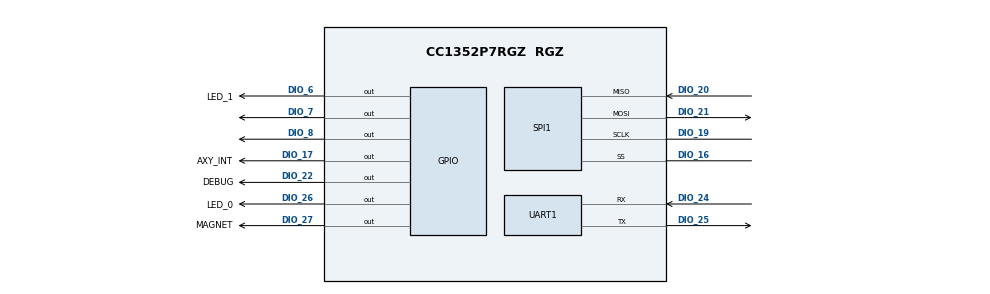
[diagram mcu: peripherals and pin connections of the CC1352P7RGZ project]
/**
 * @cliArgs --device "CC1352P7RGZ" --package "RGZ" --part "Default" --rtos "tirtos" --product "simplelink_cc13xx_cc26xx_sdk@6.10.00.29"
 * @versions {"tool":"1.12.0+2406"}
 */

/**
 * Import the modules used in this configuration.
 */
const ble         = scripting.addModule("/ti/ble5stack/ble");
const CCFG        = scripting.addModule("/ti/devices/CCFG");
const rfdesign    = scripting.addModule("/ti/devices/radioconfig/rfdesign");
const AESCCM      = scripting.addModule("/ti/drivers/AESCCM");
const AESCCM1     = AESCCM.addInstance();
const AESCTRDRBG  = scripting.addModule("/ti/drivers/AESCTRDRBG");
const AESCTRDRBG1 = AESCTRDRBG.addInstance();
const AESECB      = scripting.addModule("/ti/drivers/AESECB");
const AESECB1     = AESECB.addInstance();
const ECDH        = scripting.addModule("/ti/drivers/ECDH");
const ECDH1       = ECDH.addInstance();
const GPIO        = scripting.addModule("/ti/drivers/GPIO");
const GPIO1       = GPIO.addInstance();
const GPIO2       = GPIO.addInstance();
const GPIO3       = GPIO.addInstance();
const GPIO4       = GPIO.addInstance();
const GPIO5       = GPIO.addInstance();
const GPIO6       = GPIO.addInstance();
const GPIO7       = GPIO.addInstance();
const NVS         = scripting.addModule("/ti/drivers/NVS");
const NVS1        = NVS.addInstance();
const NVS2        = NVS.addInstance();
const NVS3        = NVS.addInstance();
const Power       = scripting.addModule("/ti/drivers/Power");
const RF          = scripting.addModule("/ti/drivers/RF");
const SPI         = scripting.addModule("/ti/drivers/SPI", {}, false);
const SPI1        = SPI.addInstance();
const TRNG        = scripting.addModule("/ti/drivers/TRNG");
const TRNG1       = TRNG.addInstance();
const UART        = scripting.addModule("/ti/drivers/UART", {}, false);
const UART1       = UART.addInstance();

/**
 * Write custom configuration values to the imported modules.
 */
ble.deviceRole                                            = "PERIPHERAL_CFG+CENTRAL_CFG";
ble.disDevBySerUuid                                       = true;
ble.numOfAdvSets                                          = 1;
ble.numOfDefAdvSets                                       = 1;
ble.maxConnNum                                            = 1;
ble.disableDisplayModule                                  = true;
ble.advRptFields                                          = ["SCAN_ADVRPT_FLD_ADDRESS","SCAN_ADVRPT_FLD_ADDRTYPE","SCAN_ADVRPT_FLD_RSSI"];
ble.randomAddress                                         = "A2:00:00:00:00:00";
ble.addressMode                                           = "ADDRMODE_PUBLIC";
ble.deviceName                                            = "Juxta";
ble.bondMITMProtection                                    = false;
ble.radioConfig.txPower                                   = "0";
ble.radioConfig.codeExportConfig.$name                    = "ti_devices_radioconfig_code_export_param0";
ble.connUpdateParamsPeripheral.$name                      = "ti_ble5stack_general_ble_conn_update_params0";
ble.connUpdateParamsPeripheral.reqMinConnInt              = 100;
ble.connUpdateParamsPeripheral.reqMaxConnInt              = 200;
ble.advSet1.$name                                         = "ti_ble5stack_broadcaster_advertisement_set0";
ble.advSet1.advParam1.$name                               = "ti_ble5stack_broadcaster_advertisement_params0";
ble.advSet1.advData1.$name                                = "ti_ble5stack_broadcaster_advertisement_data0";
ble.advSet1.advData1.GAP_ADTYPE_FLAGS                     = true;
ble.advSet1.advData1.advertisingFlags                     = ["GAP_ADTYPE_FLAGS_BREDR_NOT_SUPPORTED","GAP_ADTYPE_FLAGS_GENERAL"];
ble.advSet1.advData1.GAP_ADTYPE_16BIT_MORE                = true;
ble.advSet1.advData1.numOfUUIDs16More                     = 1;
ble.advSet1.advData1.UUID016More                          = 0xA2A2;
ble.advSet1.scanRes1.$name                                = "ti_ble5stack_broadcaster_advertisement_data1";
ble.advSet1.scanRes1.GAP_ADTYPE_SLAVE_CONN_INTERVAL_RANGE = true;
ble.advSet1.scanRes1.maxConnInterval                      = 130;
ble.advSet1.scanRes1.GAP_ADTYPE_POWER_LEVEL               = true;
ble.connUpdateParamsCentral.$name                         = "ti_ble5stack_general_ble_conn_update_params1";

CCFG.xoscCapArrayDelta        = 0xC1;
CCFG.enableBootloaderBackdoor = true;
CCFG.dioBootloaderBackdoor    = 15;
CCFG.levelBootloaderBackdoor  = "Active low";
CCFG.srcClkLF                 = "LF RCOSC";
CCFG.ccfgTemplate.$name       = "ti_devices_CCFG_CCFGCC26XXTemplate0";

rfdesign.fbSub1g = "none";
rfdesign.pa20    = "none";

AESCCM1.$name = "CONFIG_AESCCM0";

AESCTRDRBG1.$name              = "CONFIG_AESCTRDRBG_0";
AESCTRDRBG1.aesctrObject.$name = "CONFIG_AESCTR_0";

AESECB1.$name = "CONFIG_AESECB0";

ECDH1.$name = "CONFIG_ECDH0";

GPIO1.$name           = "LED_1";
GPIO1.mode            = "Output";
GPIO1.outputStrength  = "Low";
GPIO1.gpioPin.$assign = "DIO_6";

GPIO2.$name           = "AXY_INT";
GPIO2.pull            = "Pull Up";
GPIO2.gpioPin.$assign = "DIO_17";

GPIO3.$name            = "DEBUG";
GPIO3.callbackFunction = "";
GPIO3.pull             = "Pull Up";
GPIO3.gpioPin.$assign  = "DIO_22";

GPIO4.$name           = "LED_0";
GPIO4.mode            = "Output";
GPIO4.outputStrength  = "Low";
GPIO4.gpioPin.$assign = "DIO_26";

GPIO5.$name           = "CONFIG_GPIO_BTN1";
GPIO5.pull            = "Pull Down";
GPIO5.gpioPin.$assign = "DIO_7";

GPIO6.$name           = "CONFIG_GPIO_BTN2";
GPIO6.pull            = "Pull Down";
GPIO6.gpioPin.$assign = "DIO_8";

GPIO7.$name           = "MAGNET";
GPIO7.pull            = "Pull Up";
GPIO7.gpioPin.$assign = "DIO_27";

NVS1.$name                    = "CONFIG_NVSINTERNAL";
NVS1.internalFlash.$name      = "ti_drivers_nvs_NVSCC26XX0";
NVS1.internalFlash.regionBase = 0x48000;
NVS1.internalFlash.regionSize = 0x4000;

NVS2.$name                    = "NVS_JUXTA_DATA";
NVS2.internalFlash.$name      = "ti_drivers_nvs_NVSCC26XX1";
NVS2.internalFlash.regionBase = 0x10000;
NVS2.internalFlash.regionSize = 0x4000;

NVS3.$name                    = "NVS_JUXTA_CONFIG";
NVS3.internalFlash.$name      = "ti_drivers_nvs_NVSCC26XX2";
NVS3.internalFlash.regionBase = 0x14000;

SPI1.$name                          = "CONFIG_SPI";
SPI1.mode                           = "Four Pin SS Active Low";
SPI1.spi.sclkPin.$assign            = "DIO_19";
SPI1.spi.misoPin.$assign            = "DIO_20";
SPI1.spi.mosiPin.$assign            = "DIO_21";
SPI1.spi.ssPin.$assign              = "DIO_16";
SPI1.sclkPinInstance.outputStrength = "Low";
SPI1.mosiPinInstance.outputStrength = "Low";
SPI1.ssPinInstance.outputStrength   = "Low";

TRNG1.$name = "CONFIG_TRNG_0";

UART1.$name               = "JUXTA_UART";
UART1.uart.txPin.$assign  = "DIO_25";
UART1.uart.rxPin.$assign  = "DIO_24";
UART1.txPinInstance.$name = "CONFIG_GPIO_0";
UART1.rxPinInstance.$name = "CONFIG_GPIO_1";

/**
 * Pinmux solution for unlocked pins/peripherals. This ensures that minor changes to the automatic solver in a future
 * version of the tool will not impact the pinmux you originally saw.  These lines can be completely deleted in order to
 * re-solve from scratch.
 */
SPI1.spi.$suggestSolution              = "SSI0";
SPI1.spi.dmaRxChannel.$suggestSolution = "DMA_CH3";
SPI1.spi.dmaTxChannel.$suggestSolution = "DMA_CH4";
UART1.uart.$suggestSolution            = "UART0";
